# ESP32-S31 register map
Vendor: ESPRESSIF SYSTEMS (SHANGHAI) CO., LTD.; Series: ESP32 S-Series; File version: 1
CPU: RV32IMAFC r0p0, little endian, no MPU, FPU, 0 interrupt priority bits
Address unit: 32 bits
Registers are 32-bit, read-write, reset 0x0 unless marked. A register's access mark holds for its fields unless they carry their own. Offsets are from the block's base; [hi:lo] are bit positions.

## GMAC (part 3 of 6) — GMAC Peripheral
Base 0x20350000
0x704 REGISTER449_SUBSECONDINCREMENTREGISTER — Contains the 8bit value by which the SubSecond register is incremented This register is present only when IEEE1588 timestamping is enabled without an external timestamp input
  [7:0] SSINC — Subsecond Increment Value The value programmed in this field is accumulated every clock cycle _of clk_ptp_i_ with the contents of the subsecond register For example, when PTP clock is 50 MHz _period is 20 ns_, you should program 20 _0x14_ when the System Time Nanoseconds register has an accuracy of 1 ns [Bit 9 _TSCTRLSSR_ is set in Register 448 _Timestamp Control Register_] When TSCTRLSSR is clear, the Nanoseconds register has a resolution of ~0465ns In this case, you should program a value of 43 _0x2B_ that is derived by 20ns/0465
0x708 REGISTER450_SYSTEMTIMESECONDSREGISTER ro — Contains the lower 32 bits of the seconds field of the system time This register is present only when IEEE1588 timestamping is enabled without an external timestamp input
  [31:0] TSS_RO — Timestamp Second The value in this field indicates the current value in seconds of the System Time maintained by the MAC
0x70C REGISTER451_SYSTEMTIMENANOSECONDSREGISTER ro — Contains 32 bits of the nanoseconds field of the system time This register is only present when IEEE1588 timestamping is enabled without an external timestamp input
  [30:0] TSSS_RO — Timestamp Sub Seconds The value in this field has the sub second representation of time, with an accuracy of 046 ns When Bit 9 _TSCTRLSSR_ is set in Register 448 _Timestamp Control Register_, each bit represents 1 ns and the maximum value is 0x3B9A_C9FF, after which it rollsover to zero
0x710 REGISTER452_SYSTEMTIMESECONDSUPDATEREGISTER — Contains the lower 32 bits of the seconds field to be written to, added to, or subtracted from the System Time value This register is only present when IEEE1588 timestamping is enabled without an external timestamp input
  [31:0] TSS — TIMESTAMP SECOND THE VALUE IN THIS FIELD INDICATES THE TIME IN SECONDS TO BE INITIALIZED OR ADDED TO THE SYSTEM TIME
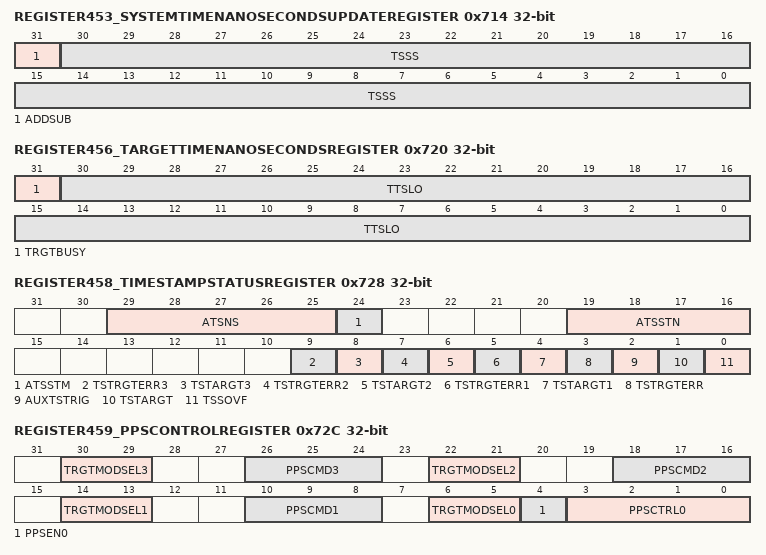
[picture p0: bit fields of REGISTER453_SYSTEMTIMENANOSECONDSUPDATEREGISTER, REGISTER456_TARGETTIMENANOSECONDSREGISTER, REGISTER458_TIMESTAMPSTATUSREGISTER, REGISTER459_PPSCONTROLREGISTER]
0x714 REGISTER453_SYSTEMTIMENANOSECONDSUPDATEREGISTER — Contains 32 bits of the nanoseconds field to be written to, added to, or subtracted from the System Time value This register is only present when IEEE1588 timestamping is enabled without an external timestamp input
  [31] ADDSUB — Add or Subtract Time When this bit is set, the time value is subtracted with the contents of the update register When this bit is reset, the time value is added with the contents of the update register
  [30:0] TSSS — Timestamp Sub Seconds The value in this field has the sub second representation of time, with an accuracy of 046 ns When Bit 9 _TSCTRLSSR_ is set in Register 448 _Timestamp Control Register_, each bit represents 1 ns and the programmed value should not exceed 0x3B9A_C9FF
0x718 REGISTER454_TIMESTAMPADDENDREGISTER — This register is used by the software to readjust the clock frequency linearly to match the master clock frequency This register is only present when IEEE1588 timestamping is enabled without an external timestamp input
  [31:0] TSAR — Timestamp Addend Register This field indicates the 32bit time value to be added to the Accumulator register to achieve time synchronization
0x71C REGISTER455_TARGETTIMESECONDSREGISTER — Contains the higher 32 bits of time to be compared with the system time for interrupt event generation or to start the PPS signal output generation This register is present only when IEEE1588 timestamping is enabled without an external timestamp input
  [31:0] TSTR — Target Time Seconds Register This register stores the time in seconds When the timestamp value matches or exceeds both Target Timestamp registers, then based on Bits [6:5] of Register 459 _PPS Control Register_, the MAC starts or stops the PPS signal output and generates an interrupt _if enabled_
0x720 REGISTER456_TARGETTIMENANOSECONDSREGISTER — Contains the lower 32 bits of time to be compared with the system time for interrupt event generation or to start the PPS signal output generation This register is present only when IEEE1588 timestamping is enabled without an external timestamp input
  [31] TRGTBUSY — Target Time Register Busy The MAC sets this bit when the PPSCMD field _Bit [3:0]_ in Register 459 _PPS Control Register_ is programmed to 010 or 011 Programming the PPSCMD field to 010 or 011, instructs the MAC to synchronize the Target Time Registers to the PTP clock domain The MAC clears this bit after synchronizing the Target Time Registers to the PTP clock domain The application must not update the Target Time Registers when this bit is read as 1 Otherwise, the synchronization of the previous programmed time gets corrupted This bit is reserved when the Enable Flexible PulsePerSecond Output feature is not selected
  [30:0] TTSLO — Target Timestamp Low Register This register stores the time in _signed_ nanoseconds When the value of the timestamp matches the both Target Timestamp registers, then based on the TRGTMODSEL0 field _Bits [6:5]_ in Register 459 _PPS Control Register_, the MAC starts or stops the PPS signal output and generates an interrupt _if enabled_ This value should not exceed 0x3B9A_C9FF when Bit 9 _TSCTRLSSR_ is set in Register 448 _Timestamp Control Register_ The actual start or stop time of the PPS signal output may have an error margin up to one unit of subsecond increment value
0x724 REGISTER457_SYSTEMTIMEHIGHERWORDSECONDSREGISTER — Contains the most significant 16bits of the timestamp seconds value This register is optional and can be selected using the parameter mentioned in “IEEE 1588 Timestamp Block” on page 492
  [15:0] TSHWR — Timestamp Higher Word Register This field contains the most significant 16bits of the timestamp seconds value This register is optional and can be selected using the Enable IEEE 1588 Higher Word Register option during core configuration The register is directly written to initialize the value This register is incremented when there is an overflow from the 32bits of the System Time Seconds register
0x728 REGISTER458_TIMESTAMPSTATUSREGISTER access per field — Contains the PTP status This register is available only when the advanced IEEE 1588 timestamp feature is selected
  [29:25] ATSNS ro — Number of Auxiliary Timestamp Snapshots This field indicates the number of Snapshots available in the FIFO A value equal to the selected depth of FIFO _4, 8, or 16_ indicates that the Auxiliary Snapshot FIFO is full These bits are cleared _to 00000_ when the Auxiliary snapshot FIFO clear bit is set This bit is valid only if the Add IEEE 1588 Auxiliary Snapshot option is selected during core configuration
  [24] ATSSTM ro — Auxiliary Timestamp Snapshot Trigger Missed
  [19:16] ATSSTN rw — Auxiliary Timestamp Snapshot Trigger Identifier These bits identify the Auxiliary trigger inputs for which the timestamp available in the Auxiliary Snapshot Register is applicable When more than one bit is set at the same time, it means that corresponding auxiliary triggers were sampled at the same clock These bits are applicable only if the number of Auxiliary snapshots is more than one One bit is assigned for each trigger as shown in the following list: Bit 16: Auxiliary trigger 0 Bit 17: Auxiliary trigger 1 Bit 18: Auxiliary trigger 2 Bit 19: Auxiliary trigger 3 The software can read this register to find the triggers that are set when the timestamp is taken
  [9] TSTRGTERR3 rw — Timestamp Target Time Error This bit is set when the target time, being programmed in Register 496 and Register 497, is already elapsed This bit is cleared when read by the application
  [8] TSTARGT3 rw — Timestamp Target Time Reached for Target Time PPS3 When set, this bit indicates that the value of system time is greater than or equal to the value specified in Register 496 _PPS3 Target Time High Register_ and Register 497 _PPS3 Target Time Low Register_
  [7] TSTRGTERR2 rw — Timestamp Target Time Error This bit is set when the target time, being programmed in Register 488 and Register 489, is already elapsed This bit is cleared when read by the application
  [6] TSTARGT2 rw — Timestamp Target Time Reached for Target Time PPS2 When set, this bit indicates that the value of system time is greater than or equal to the value specified in Register 488 _PPS2 Target Time High Register_ and Register 489 _PPS2 Target Time Low Register_
  [5] TSTRGTERR1 rw — Timestamp Target Time Error This bit is set when the target time, being programmed in Register 480 and Register 481, is already elapsed This bit is cleared when read by the application
  [4] TSTARGT1 rw — Timestamp Target Time Reached for Target Time PPS1 When set, this bit indicates that the value of system time is greater than or equal to the value specified in Register 480 _PPS1 Target Time High Register_ and Register 481 _PPS1 Target Time Low Register_
  [3] TSTRGTERR rw — Timestamp Target Time Error This bit is set when the target time, being programmed in Register 455 and Register 456, is already elapsed This bit is cleared when read by the application
  [2] AUXTSTRIG rw — Auxiliary Timestamp Trigger Snapshot This bit is set high when the auxiliary snapshot is written to the FIFO This bit is valid only if the Enable IEEE 1588 Auxiliary Snapshot feature is selected
  [1] TSTARGT rw — Timestamp Target Time Reached When set, this bit indicates that the value of system time is greater than or equal to the value specified in the Register 455 _Target Time Seconds Register_ and Register 456 _Target Time Nanoseconds Register_
  [0] TSSOVF rw — Timestamp Seconds Overflow When set, this bit indicates that the seconds value of the timestamp _when supporting version 2 format_ has overflowed beyond 32’hFFFF_FFFF
0x72C REGISTER459_PPSCONTROLREGISTER — This register is used to control the interval of the PPS signal output This register is available only when the advanced IEEE 1588 timestamp feature is selected
  [30:29] TRGTMODSEL3 — Target Time Register Mode for PPS3 Output This field indicates the Target Time registers _register 496 and 497_ mode for PPS3 output signal This field is similar to the TRGTMODSEL0 field
  [26:24] PPSCMD3 — Flexible PPS3 Output Control This field controls the flexible PPS3 output _ptp_pps_o[3]_ signal This field is similar to PPSCMD0[2:0] in functionality
  [22:21] TRGTMODSEL2 — Target Time Register Mode for PPS2 Output This field indicates the Target Time registers _register 488 and 489_ mode for PPS2 output signal This field is similar to the TRGTMODSEL0 field
  [18:16] PPSCMD2 — Flexible PPS2 Output Control This field controls the flexible PPS2 output _ptp_pps_o[2]_ signal This field is similar to PPSCMD0[2:0] in functionality
  [14:13] TRGTMODSEL1 — Target Time Register Mode for PPS1 Output This field indicates the Target Time registers _register 480 and 481_ mode for PPS1 output signal This field is similar to the TRGTMODSEL0 field
  [10:8] PPSCMD1 — Flexible PPS1 Output Control This field controls the flexible PPS1 output _ptp_pps_o[1]_ signal This field is similar to PPSCMD0[2:0] in functionality
  [6:5] TRGTMODSEL0 — Target Time Register Mode for PPS0 Output This field indicates the Target Time registers _register 455 and 456_ mode for PPS0 output signal: 00: Indicates that the Target Time registers are programmed only for generating the interrupt event 01: Reserved 10: Indicates that the Target Time registers are programmed for generating the interrupt event and starting or stopping the generation of the PPS0 output signal 11: Indicates that the Target Time registers are programmed only for starting or stopping the generation of the PPS0 output signal No interrupt is asserted
  [4] PPSEN0 — Flexible PPS Output Mode Enable When set low, Bits [3:0] function as PPSCTRL _backward compatible_ When set high, Bits[3:0] function as PPSCMD
  [3:0] PPSCTRL0 — PPSCTRL0: PPS0 Output Frequency Control This field controls the frequency of the PPS0 output _ptp_pps_o[0]_ signal The default value of PPSCTRL is 0000, and the PPS output is 1 pulse _of width clk_ptp_i_ every second For other values of PPSCTRL, the PPS output becomes a generated clock of following frequencies: 0001: The binary rollover is 2 Hz, and the digital rollover is 1 Hz 0010: The binary rollover is 4 Hz, and the digital rollover is 2 Hz 0011: The binary rollover is 8 Hz, and the digital rollover is 4 Hz 0100: The binary rollover is 16 Hz, and the digital rollover is 8 Hz 1111: The binary rollover is 32768 KHz, and the digital rollover is 16384 KHz Note: In the binary rollover mode, the PPS output _ptp_pps_o_ has a duty cycle of 50 percent with these frequencies In the digital rollover mode, the PPS output frequency is an average number The actual clock is of different frequency that gets synchronized every second For example: When PPSCTRL = 0001, the PPS _1 Hz_ has a low period of 537 ms and a high period of 463 ms When PPSCTRL = 0010, the PPS _2 Hz_ is a sequence of: One clock of 50 percent duty cycle and 537 ms period Second clock of 463 ms period _268 ms low and 195 ms high_ When PPSCTRL = 0011, the PPS _4 Hz_ is a sequence of: Three clocks of 50 percent duty cycle and 268 ms period Fourth clock of 195 ms period _134 ms low and 61 ms high_ This behavior is because of the nonlinear toggling of bits in the digital rollover mode in Register 451 _System Time Nanoseconds Register_ / PPSCMD0: Flexible PPS0 Output _ptp_pps_o[0]_ Control Programming these bits with a nonzero value instructs the MAC to initiate an event When the command is transferred or synchronized to the PTP clock domain, these bits get cleared automatically The Software should ensure that these bits are programmed only when they are “allzero” The following list describes the values of PPSCMD0: 0000: No Command 0001: START Single Pulse This command generates single pulse rising at the start point defined in Target Time Registers _register 455 and 456_ and of a duration defined in the PPS0 Width Register 0010: START Pulse Train This command generates the train of pulses rising at the start point defined in the Target Time Registers and of a duration defined in the PPS0 Width Register and repeated at interval defined in the PPS Interval Register By default, the PPS pulse train is freerunning unless stopped by 'STOP Pulse train at time' or 'STOP Pulse Train immediately' commands 0011: Cancel START This command cancels the START Single Pulse and START Pulse Train commands if the system time has not crossed the programmed start time 0100: STOP Pulse train at time This command stops the train of pulses initiated by the START Pulse Train command _PPSCMD = 0010_ after the time programmed in the Target Time registers elapses 0101: STOP Pulse Train immediately This command immediately stops the train of pulses initiated by the START Pulse Train command _PPSCMD = 0010_ 0110: Cancel STOP Pulse train This command cancels the STOP pulse train at time command if the programmed stop time has not elapsed The PPS pulse train becomes freerunning on the successful execution of this command 01111111: Reserved
0x730 REGISTER460_AUXILIARYTIMESTAMPNANOSECONDSREGISTER ro — Contains the lower 32 bits _nanoseconds field_ of the auxiliary timestamp register
  [30:0] AUXTSLO — Contains the lower 31 bits _nanoseconds field_ of the auxiliary timestamp
0x734 REGISTER461_AUXILIARYTIMESTAMPSECONDSREGISTER ro — Contains the lower 32 bits of the Seconds field of the auxiliary timestamp register
  [31:0] AUXTSHI — Contains the lower 32 bits of the Seconds field of the auxiliary timestamp
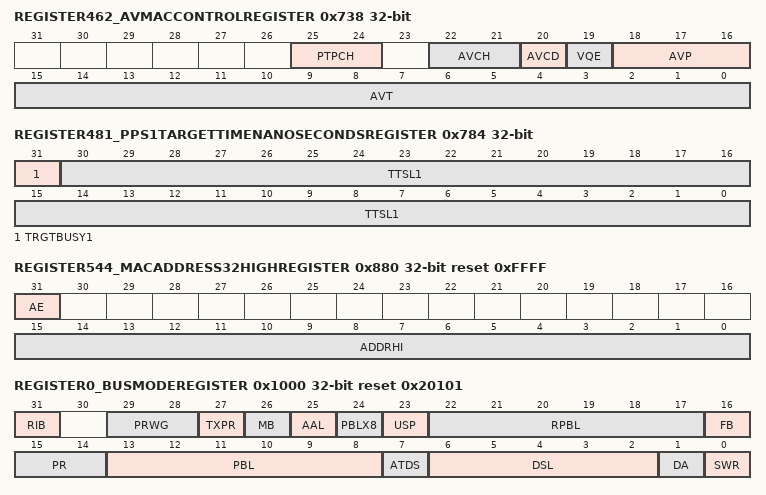
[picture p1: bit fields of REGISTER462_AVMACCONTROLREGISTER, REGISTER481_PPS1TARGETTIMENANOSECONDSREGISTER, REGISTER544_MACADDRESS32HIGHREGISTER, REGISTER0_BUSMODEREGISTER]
0x738 REGISTER462_AVMACCONTROLREGISTER — Controls the AV traffic and queue management in the MAC Receiver This register is present only when you select the AV feature in coreConsultant
  [25:24] PTPCH — Channel for Queuing the PTP Packets This field specifies the channel on which the untagged PTP packets, sent over the Ethernet payload and not over IPv4 or IPv6, are queued 00: Channel 0 01: Channel 1 10: Channel 2 11: Reserved These bits are reserved if the receive paths of Channel 1 or Channel 2 are not enabled
  [22:21] AVCH — Channel for Queuing the AV Control Packets This field specifies the channel on which the received untagged AV control packets are queued 00: Channel 0 01: Channel 1 10: Channel 2 11: Reserved These bits are reserved if the receive paths of Channel 1 or Channel 2 are not enabled
  [20] AVCD — AV Channel Disable When this bit is set, the MAC forwards all packets to the default Channel 0 and the values programmed in the AVP, AVCH, and PTPCH fields are ignored This bit is reserved and readonly if Channel 1 or Channel 2 receive paths are not selected during core configuration
  [19] VQE — VLAN Tagged NonAV Packets Queueing Enable When this bit is set, the MAC also queues nonAV VLAN tagged packets into the available channels according to the value of the AVP bits This bit is reserved and readonly if Channel 1 and Channel 2 Receive paths are not selected during core configuration
  [18:16] AVP — AV Priority for Queuing The value programmed in these bits control the receive channel _0, 1, or 2_ to which an AV packet with a given priority must be queued If only Channel 1 receive path is enabled, the AV packets with priority value greater than or equal to the programmed value are queued on Channel 1 and all other packets are queued on Channel 0 If Channel 2 receive path is also enabled, the AV packets with priority value greater than or equal to the programmed value are queued on Channel 2 The AV packets with value less than the programmed value on Channel 1 and all other packets are queued on Channel 0 These bits are applicable only if at least one additional receive channel is selected in the AV mode
  [15:0] AVT — AV EtherType Value This field contains the value that is compared with the EtherType field of the incoming _tagged or untagged_ Ethernet frame to detect an AV packet
0x760 REGISTER472_PPS0INTERVALREGISTER — Contains the number of units of subsecond increment value between the rising edges of PPS0 signal output This register is available only when the flexible PPS feature is selected
  [31:0] PPSINT — PPS0 Output Signal Interval These bits store the interval between the rising edges of PPS0 signal output in terms of units of subsecond increment value You need to program one value less than the required interval For example, if the PTP reference clock is 50 MHz _period of 20ns_, and desired interval between rising edges of PPS0 signal output is 100ns _that is, five units of subsecond increment value_, then you should program value 4 _5 1_ in this register
0x764 REGISTER473_PPS0WIDTHREGISTER — Contains the number of units of subsecond increment value between the rising and corresponding falling edges of PPS0 signal output This register is available only when the flexible PPS feature is selected
  [31:0] PPSWIDTH — PPS0 Output Signal Width These bits store the width between the rising edge and corresponding falling edge of the PPS0 signal output in terms of units of subsecond increment value You need to program one value less than the required interval For example, if PTP reference clock is 50 MHz _period of 20ns_, and desired width between the rising and corresponding falling edges of PPS0 signal output is 80ns _that is, four units of subsecond increment value_, then you should program value 3 _4 1_ in this register Note: The value programmed in this register must be lesser than the value programmed in Register 472 _PPS0 Interval Register_
0x780 REGISTER480_PPS1TARGETTIMESECONDSREGISTER — Contains the higher 32 bits of time to be compared with the system time to generate the interrupt event or to start generating the PPS1 output signal This register is present only when IEEE1588 timestamping is enabled without an external timestamp input and at least one additional PPS output is selected
  [31:0] TSTRH1 — PPS1 Target Time Seconds Register This register stores the time in seconds When the timestamp value matches or exceeds both Target Timestamp registers, then based on Bits [14:13], TRGTMODSEL1, of Register 459 _PPS Control Register_, the MAC starts or stops the PPS signal output and generates an interrupt _if enabled_
0x784 REGISTER481_PPS1TARGETTIMENANOSECONDSREGISTER — Contains the lower 32 bits of time to be compared with the system time to generate the interrupt event or to start generating the PPS1 output signal This register is present only when IEEE1588 timestamping is enabled without an external timestamp input and at least one additional PPS output is selected
  [31] TRGTBUSY1 — PPS1 Target Time Register Busy The MAC sets this bit when the PPSCMD1 field _Bits [10:8]_ in Register 459 _PPS Control Register_ is programmed to 010 or 011 Programming the PPSCMD1 field to 010 or 011 instructs the MAC to synchronize the Target Time Registers to the PTP clock domain The MAC clears this bit after synchronizing the Target Time Registers to the PTP clock domain The application must not update the Target Time Registers when this bit is read as 1 Otherwise, the synchronization of the previous programmed time gets corrupted
  [30:0] TTSL1 — Target Time Low for PPS1 Register This register stores the time in _signed_ nanoseconds When the value of the timestamp matches the both Target Timestamp registers, then based on the TRGTMODSEL1 field _Bits [14:13]_ in Register 459 _PPS Control Register_, the MAC starts or stops the PPS signal output and generates an interrupt _if enabled_ This value should not exceed 0x3B9A_C9FF when Bit 9 _TSCTRLSSR_ is set in Register 448 _Timestamp Control Register_ The actual start or stop time of the PPS signal output may have an error margin up to one unit of subsecond increment value
0x880 REGISTER544_MACADDRESS32HIGHREGISTER reset 0xFFFF — Contains the higher 16 bits of the 33rd MAC address This register is present only when Enable Additional 32 MAC Address Registers is selected in coreConsultant _See Table 78_
  [31] AE — Address Enable When this bit is set, the Address filter module uses the 33rd MAC address for perfect filtering When reset, the address filter module ignores the address for filtering
  [15:0] ADDRHI — MAC Address32 [47:32] This field contains the upper 16 bits _47:32_ of the 33rd 6byte MAC address
0x1000 REGISTER0_BUSMODEREGISTER reset 0x20101 — Controls the Host Interface Mode
  [31] RIB — Rebuild INCRx Burst When this bit is set high and the AHB master gets an EBT _Retry, Split, or Losing bus grant_, the AHB master interface rebuilds the pending beats of any burst transfer initiated with INCRx The AHB master interface rebuilds the beats with a combination of specified bursts with INCRx and SINGLE By default, the AHB master interface rebuilds pending beats of an EBT with an unspecified _INCR_ burst This bit is valid only in the GMACAHB configuration It is reserved in all other configuration
  [29:28] PRWG — Channel Priority Weights This field sets the priority weights for Channel 0 during the roundrobin arbitration between the DMA channels for the system bus 00: The priority weight is 1 01: The priority weight is 2 10: The priority weight is 3 11: The priority weight is 4 This field is present in all DWC_gmac configurations except GMACAXI when you select the AV feature Otherwise, this field is reserved and readonly _RO_ For more information about the priority weights of DMA channels, see “DMA Arbiter Functions” on page 167
  [27] TXPR — Transmit Priority When set, this bit indicates that the transmit DMA has higher priority than the receive DMA during arbitration for the systemside bus In the GMACAXI configuration, this bit is reserved and readonly _RO_ For more information about the priority scheme between the transmit and receive paths, see Table 412 in “DMA Arbiter Functions” on page 167
  [26] MB — Mixed Burst When this bit is set high and the FB bit is low, the AHB master interface starts all bursts of length more than 16 with INCR _undefined burst_, whereas it reverts to fixed burst transfers _INCRx and SINGLE_ for burst length of 16 and less This bit is valid only in the GMACAHB configuration and reserved in all other configuration
  [25] AAL — AddressAligned Beats When this bit is set high and the FB bit is equal to 1, the AHB or AXI interface generates all bursts aligned to the start address LS bits If the FB bit is equal to 0, the first burst _accessing the start address of data buffer_ is not aligned, but subsequent bursts are aligned to the address This bit is valid only in the GMACAHB and GMACAXI configurations and is reserved _RO with default value 0_ in all other configurations
  [24] PBLX8 — PBLx8 Mode When set high, this bit multiplies the programmed PBL value _Bits [22:17] and Bits[13:8]_ eight times Therefore, the DMA transfers the data in 8, 16, 32, 64, 128, and 256 beats depending on the PBL value Note: This bit function is not backward compatible Before release 350a, this bit was 4xPBL
  [23] USP — Use Separate PBL When set high, this bit configures the Rx DMA to use the value configured in Bits [22:17] as PBL The PBL value in Bits [13:8] is applicable only to the Tx DMA operations When reset to low, the PBL value in Bits [13:8] is applicable for both DMA engines
  [22:17] RPBL — Rx DMA PBL This field indicates the maximum number of beats to be transferred in one Rx DMA transaction This is the maximum value that is used in a single block Read or Write The Rx DMA always attempts to burst as specified in the RPBL bit each time it starts a Burst transfer on the host bus You can program RPBL with values of 1, 2, 4, 8, 16, and 32 Any other value results in undefined behavior This field is valid and applicable only when USP is set high
  [16] FB — Fixed Burst This bit controls whether the AHB or AXI master interface performs fixed burst transfers or not When set, the AHB interface uses only SINGLE, INCR4, INCR8, or INCR16 during start of the normal burst transfers When reset, the AHB or AXI interface uses SINGLE and INCR burst transfer operations For more information, see Bit 0 _UNDEF_ of the AXI Bus Mode register in the GMACAXI configuration
  [15:14] PR — Priority Ratio These bits control the priority ratio in the weighted roundrobin arbitration between the Rx DMA and Tx DMA These bits are valid only when Bit 1 _DA_ is reset The priority ratio is Rx:Tx or Tx:Rx depending on whether Bit 27 _TXPR_ is reset or set 00: The Priority Ratio is 1:1 01: The Priority Ratio is 2:1 10: The Priority Ratio is 3:1 11: The Priority Ratio is 4:1 In the GMACAXI configuration, these bits are reserved and readonly _RO_ For more information about the priority scheme between the transmit and receive paths, see Table 412 in “DMA Arbiter Functions” on page 167
  [13:8] PBL — Programmable Burst Length These bits indicate the maximum number of beats to be transferred in one DMA transaction This is the maximum value that is used in a single block Read or Write The DMA always attempts to burst as specified in PBL each time it starts a Burst transfer on the host bus PBL can be programmed with permissible values of 1, 2, 4, 8, 16, and 32 Any other value results in undefined behavior When USP is set high, this PBL value is applicable only for Tx DMA transactions If the number of beats to be transferred is more than 32, then perform the following steps: 1 Set the PBLx8 mode 2 Set the PBL For example, if the maximum number of beats to be transferred is 64, then first set PBLx8 to 1 and then set PBL to 8 The PBL values have the following limitation: The maximum number of possible beats _PBL_ is limited by the size of the Tx FIFO and Rx FIFO in the MTL layer and the data bus width on the DMA The FIFO has a constraint that the maximum beat supported is half the depth of the FIFO, except when specified For different data bus widths and FIFO sizes, the valid PBL range _including x8 mode_ is provided in Table 66 on page 382
  [7] ATDS — Alternate Descriptor Size When set, the size of the alternate descriptor _described in “Alternate or Enhanced Descriptors” on page 545_ increases to 32 bytes _8 DWORDS_ This is required when the Advanced Timestamp feature or the IPC Full Checksum Offload Engine _Type 2_ is enabled in the receiver The enhanced descriptor is not required if the Advanced Timestamp and IPC Full Checksum Offload Engine _Type 2_ features are not enabled In such case, you can use the 16 bytes descriptor to save 4 bytes of memory This bit is present only when you select the Alternate Descriptor feature and any one of the following features during core configuration: Advanced Timestamp feature IPC Full Checksum Offload Engine _Type 2_ feature Otherwise, this bit is reserved and is readonly When reset, the descriptor size reverts back to 4 DWORDs _16 bytes_ This bit preserves the backward compatibility for the descriptor size In versions prior to 350a, the descriptor size is 16 bytes for both normal and enhanced descriptors In version 350a, descriptor size is increased to 32 bytes because of the Advanced Timestamp and IPC Full Checksum Offload Engine _Type 2_ features
  [6:2] DSL — Descriptor Skip Length This bit specifies the number of Word, Dword, or Lword _depending on the 32bit, 64bit, or 128bit bus_ to skip between two unchained descriptors The address skipping starts from the end of current descriptor to the start of next descriptor When the DSL value is equal to zero, the descriptor table is taken as contiguous by the DMA in Ring mode
  [1] DA — DMA Arbitration Scheme This bit specifies the arbitration scheme between the transmit and receive paths of Channel 0 0: Weighted roundrobin with Rx:Tx or Tx:Rx The priority between the paths is according to the priority specified in Bits [15:14] _PR_ and priority weights specified in Bit 27 _TXPR_ 1: Fixed priority The transmit path has priority over receive path when Bit 27 _TXPR_ is set Otherwise, receive path has priority over the transmit path In the GMACAXI configuration, these bits are reserved and are readonly _RO_ For more information about the priority scheme between the transmit and receive paths, see Table 412 in “DMA Arbiter Functions” on page 167
  [0] SWR — Software Reset When this bit is set, the MAC DMA Controller resets the logic and all internal registers of the MAC It is cleared automatically after the reset operation is complete in all of the DWC_gmac clock domains Before reprogramming any register of the DWC_gmac, you should read a zero _0_ value in this bit Note: The Software reset function is driven only by this bit Bit 0 of Register 64 _Channel 1 Bus Mode Register_ or Register 128 _Channel 2 Bus Mode Register_ has no impact on the Software reset function The reset operation is completed only when all resets in all active clock domains are deasserted Therefore, it is essential that all PHY inputs clocks _applicable for the selected PHY interface_ are present for the software reset completion The time to complete the software reset operation depends on the frequency of the slowest active clock
0x1004 REGISTER1_TRANSMITPOLLDEMANDREGISTER ro — Used by the host to instruct the DMA to poll the Transmit Descriptor list
  [31:0] TPD — Transmit Poll Demand When these bits are written with any value, the DMA reads the current descriptor to which the Register 18 _Current Host Transmit Descriptor Register_ is pointing If that descriptor is not available _owned by the Host_, the transmission returns to the Suspend state and Bit 2 _TU_ of Register 5 _Status Register_ is asserted If the descriptor is available, the transmission resumes
0x1008 REGISTER2_RECEIVEPOLLDEMANDREGISTER ro — Used by the host to instruct the DMA to poll the Receive Descriptor list
  [31:0] RPD — Receive Poll Demand When these bits are written with any value, the DMA reads the current descriptor to which the Register 19 _Current Host Receive Descriptor Register_ is pointing If that descriptor is not available _owned by the Host_, the reception returns to the Suspended state and Bit 7 _RU_ of Register 5 _Status Register_ is asserted If the descriptor is available, the Rx DMA returns to the active state
0x100C REGISTER3_RECEIVEDESCRIPTORLISTADDRESSREGISTER — Points the DMA to the start of the Receive Descriptor list
  [31:0] RDESLA — Start of Receive List This field contains the base address of the first descriptor in the Receive Descriptor list The LSB bits _1:0, 2:0, or 3:0_ for 32bit, 64bit, or 128bit bus width are ignored and internally taken as allzero by the DMA Therefore, these LSB bits are readonly _RO_
0x1010 REGISTER4_TRANSMITDESCRIPTORLISTADDRESSREGISTER — Points the DMA to the start of the Transmit Descriptor list
  [31:0] TDESLA — Start of Transmit List This field contains the base address of the first descriptor in the Transmit Descriptor list The LSB bits _1:0, 2:0, 3:0_ for 32bit, 64bit, or 128bit bus width are ignored and are internally taken as allzero by the DMA Therefore, these LSB bits are readonly _RO_
